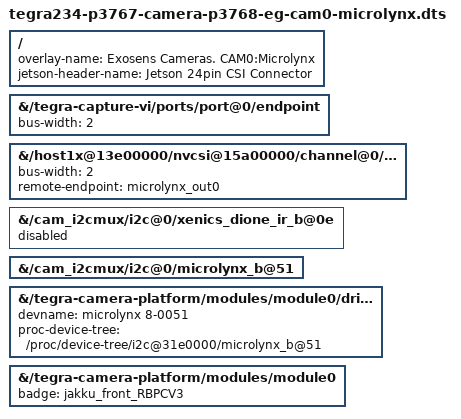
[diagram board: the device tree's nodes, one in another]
// SPDX-License-Identifier: GPL-2.0-only

/dts-v1/;
/plugin/;

#include <dt-common/jetson/tegra234-p3767-0000-common.h>

/ {
	overlay-name = "Exosens Cameras. CAM0:Microlynx";
	jetson-header-name = "Jetson 24pin CSI Connector";
	compatible = JETSON_COMPATIBLE_P3768;

	fragment@00 {
		target-path = "/tegra-capture-vi/ports/port@0/endpoint";
		__overlay__ {
			bus-width=<2>;
		};
	};

	fragment@1 {
		target-path = "/host1x@13e00000/nvcsi@15a00000/channel@0/ports/port@0/endpoint@0";
		__overlay__ {
			bus-width=<2>;
			remote-endpoint = <&microlynx_out0>;
		};
	};

   // Disable Dione cameras
	fragment@2 {
		target-path = "/cam_i2cmux/i2c@0/xenics_dione_ir_b@0e";
		__overlay__ {
         status = "disabled";
		};
	};

	// Enable Microlynx
	fragment@3 {
		target-path = "/cam_i2cmux/i2c@0/microlynx_b@51";
		__overlay__ {
         status = "okay";
		};
	};

	fragment@6 {
		target-path = "/tegra-camera-platform/modules/module0/drivernode0";
		__overlay__ {
			devname = "microlynx 8-0051";
			proc-device-tree = "/proc/device-tree/i2c@31e0000/microlynx_b@51";
		};
	};

	fragment@7 {
		target-path = "/tegra-camera-platform/modules/module0";
		__overlay__ {
			badge = "jakku_front_RBPCV3";
		};
	};

};
